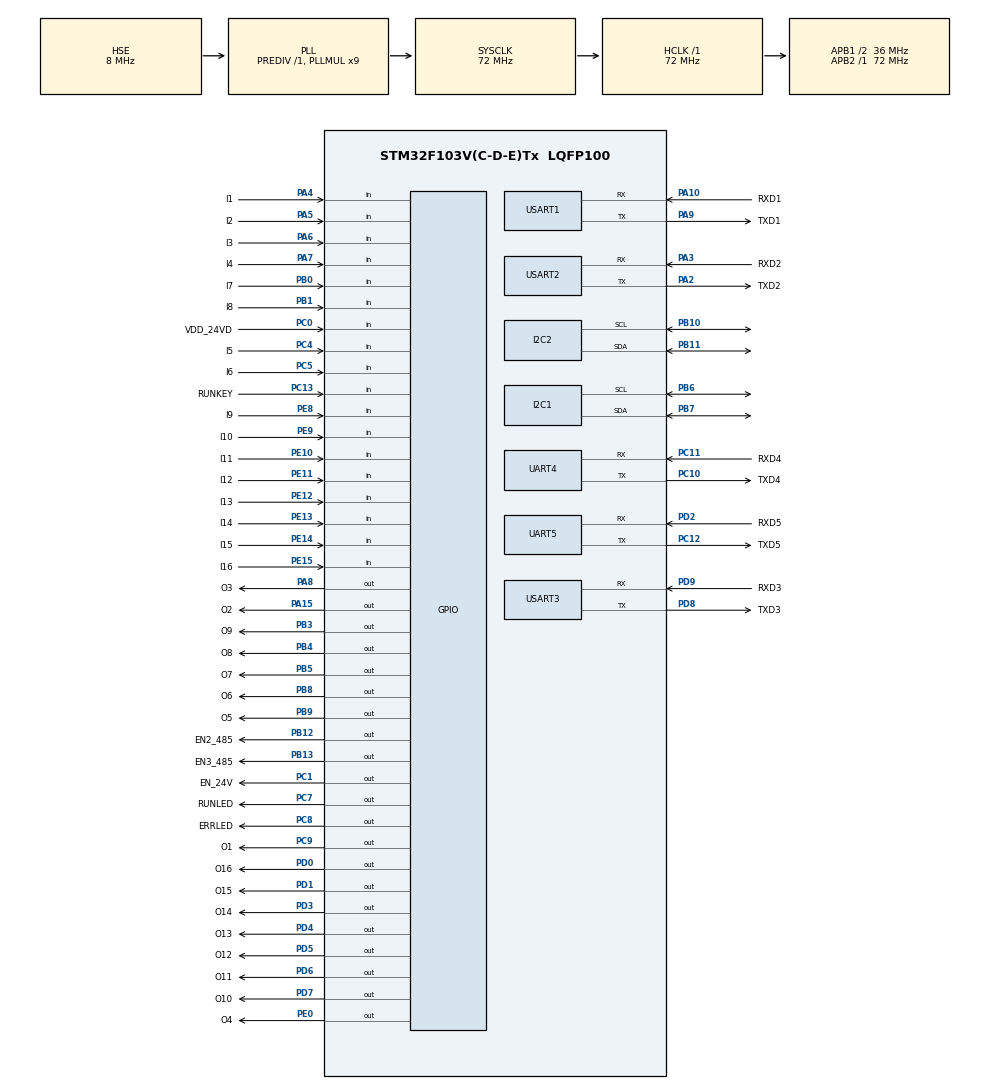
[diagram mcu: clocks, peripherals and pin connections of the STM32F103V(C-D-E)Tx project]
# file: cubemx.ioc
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Mcu.Family=STM32F1
Mcu.Name=STM32F103V(C-D-E)Tx
Mcu.Package=LQFP100
NVIC.PriorityGroup=NVIC_PRIORITYGROUP_4
NVIC.TIM1_UP_IRQn=true\:0\:0\:false\:false\:true\:true\:true\:true
NVIC.TIM2_IRQn=true\:0\:0\:false\:false\:true\:true\:true\:true
NVIC.TIM3_IRQn=true\:0\:0\:false\:false\:true\:true\:true\:true
NVIC.TIM4_IRQn=true\:0\:0\:false\:false\:true\:true\:true\:true
NVIC.TIM5_IRQn=true\:0\:0\:false\:false\:true\:true\:true\:true
NVIC.TIM6_IRQn=true\:0\:0\:false\:false\:true\:true\:true\:true
NVIC.TIM7_IRQn=true\:0\:0\:false\:false\:true\:true\:true\:true
NVIC.TIM8_UP_IRQn=true\:0\:0\:false\:false\:true\:true\:true\:true
NVIC.USART1_IRQn=true\:0\:0\:false\:false\:true\:true\:true\:true
OSC_IN.Mode=HSE-External-Oscillator
OSC_IN.Signal=RCC_OSC_IN
OSC_OUT.Mode=HSE-External-Oscillator
OSC_OUT.Signal=RCC_OSC_OUT
PA10.GPIO_Label=RXD1
PA10.Mode=Asynchronous
PA10.Signal=USART1_RX
PA13.Mode=Serial_Wire
PA13.Signal=SYS_JTMS-SWDIO
PA14.Mode=Serial_Wire
PA14.Signal=SYS_JTCK-SWCLK
PA15.GPIO_Label=O2
PA15.PinState=GPIO_PIN_RESET
PA15.Signal=GPIO_Output
PA2.GPIO_Label=TXD2
PA2.Mode=Asynchronous
PA2.Signal=USART2_TX
PA3.GPIO_Label=RXD2
PA3.Mode=Asynchronous
PA3.Signal=USART2_RX
PA4.GPIO_Label=I1
PA4.GPIO_Mode=GPIO_MODE_INPUT
PA4.GPIO_PuPd=GPIO_PULLUP
PA4.Signal=GPIO_Input
PA5.GPIO_Label=I2
PA5.GPIO_Mode=GPIO_MODE_INPUT
PA5.GPIO_PuPd=GPIO_PULLUP
PA5.Signal=GPIO_Input
PA6.GPIO_Label=I3
PA6.GPIO_Mode=GPIO_MODE_INPUT
PA6.GPIO_PuPd=GPIO_PULLUP
PA6.Signal=GPIO_Input
PA7.GPIO_Label=I4
PA7.GPIO_Mode=GPIO_MODE_INPUT
PA7.GPIO_PuPd=GPIO_PULLUP
PA7.Signal=GPIO_Input
PA8.GPIO_Label=O3
PA8.PinState=GPIO_PIN_RESET
PA8.Signal=GPIO_Output
PA9.GPIO_Label=TXD1
PA9.Mode=Asynchronous
PA9.Signal=USART1_TX
PB0.GPIO_Label=I7
PB0.GPIO_Mode=GPIO_MODE_INPUT
PB0.GPIO_PuPd=GPIO_PULLUP
PB0.Signal=GPIO_Input
PB1.GPIO_Label=I8
PB1.GPIO_Mode=GPIO_MODE_INPUT
PB1.GPIO_PuPd=GPIO_PULLUP
PB1.Signal=GPIO_Input
PB10.GPIO_Pu=GPIO_PULLUP
PB10.Mode=I2C
PB10.Signal=I2C2_SCL
PB11.GPIO_Pu=GPIO_PULLUP
PB11.Mode=I2C
PB11.Signal=I2C2_SDA
PB12.GPIO_Label=EN2_485
PB12.GPIO_Speed=GPIO_SPEED_FREQ_LOW
PB12.PinState=GPIO_PIN_SET
PB12.Signal=GPIO_Output
PB13.GPIO_Label=EN3_485
PB13.GPIO_Speed=GPIO_SPEED_FREQ_LOW
PB13.PinState=GPIO_PIN_SET
PB13.Signal=GPIO_Output
PB3.GPIO_Label=O9
PB3.GPIO_ModeDefaultOutputPP=GPIO_MODE_OUTPUT_PP
PB3.GPIO_PuPd=GPIO_NOPULL
PB3.GPIO_Speed=GPIO_SPEED_FREQ_LOW
PB3.PinState=GPIO_PIN_SET
PB3.Signal=GPIO_Output
PB4.GPIO_Label=O8
PB4.GPIO_ModeDefaultOutputPP=GPIO_MODE_OUTPUT_PP
PB4.GPIO_PuPd=GPIO_NOPULL
PB4.GPIO_Speed=GPIO_SPEED_FREQ_LOW
PB4.PinState=GPIO_PIN_SET
PB4.Signal=GPIO_Output
PB5.GPIO_Label=O7
PB5.GPIO_ModeDefaultOutputPP=GPIO_MODE_OUTPUT_PP
PB5.GPIO_PuPd=GPIO_NOPULL
PB5.GPIO_Speed=GPIO_SPEED_FREQ_LOW
PB5.PinState=GPIO_PIN_SET
PB5.Signal=GPIO_Output
PB6.GPIO_Pu=GPIO_PULLUP
PB6.Mode=I2C
PB6.Signal=I2C1_SCL
PB7.GPIO_Pu=GPIO_PULLUP
PB7.Mode=I2C
PB7.Signal=I2C1_SDA
PB8.GPIO_Label=O6
PB8.GPIO_ModeDefaultOutputPP=GPIO_MODE_OUTPUT_PP
PB8.GPIO_PuPd=GPIO_NOPULL
PB8.GPIO_Speed=GPIO_SPEED_FREQ_LOW
PB8.PinState=GPIO_PIN_SET
PB8.Signal=GPIO_Output
PB9.GPIO_Label=O5
PB9.GPIO_ModeDefaultOutputPP=GPIO_MODE_OUTPUT_PP
PB9.GPIO_PuPd=GPIO_NOPULL
PB9.GPIO_Speed=GPIO_SPEED_FREQ_LOW
PB9.PinState=GPIO_PIN_SET
PB9.Signal=GPIO_Output
PC0.GPIO_Label=VDD_24VD
PC0.Signal=GPIO_Input
PC1.GPIO_Label=EN_24V
PC1.GPIO_Speed=GPIO_SPEED_FREQ_LOW
PC1.Signal=GPIO_Output
PC10.GPIO_Label=TXD4
PC10.Mode=Asynchronous
PC10.Signal=UART4_TX
PC11.GPIO_Label=RXD4
PC11.Mode=Asynchronous
PC11.Signal=UART4_RX
PC12.GPIO_Label=TXD5
PC12.Mode=Asynchronous
PC12.Signal=UART5_TX
PC13-TAMPER-RTC.GPIO_Label=RUNKEY
PC13-TAMPER-RTC.Signal=GPIO_Input
PC14-OSC32_IN.Mode=LSE-External-Oscillator
PC14-OSC32_IN.Signal=RCC_OSC32_IN
PC15-OSC32_OUT.Mode=LSE-External-Oscillator
PC15-OSC32_OUT.Signal=RCC_OSC32_OUT
PC4.GPIO_Label=I5
PC4.GPIO_Mode=GPIO_MODE_INPUT
PC4.GPIO_PuPd=GPIO_PULLUP
PC4.Signal=GPIO_Input
PC5.GPIO_Label=I6
PC5.GPIO_Mode=GPIO_MODE_INPUT
PC5.GPIO_PuPd=GPIO_PULLUP
PC5.Signal=GPIO_Input
PC7.GPIO_Label=RUNLED
PC7.GPIO_ModeDefaultOutputPP=GPIO_MODE_OUTPUT_PP
PC7.GPIO_PuPd=GPIO_NOPULL
PC7.GPIO_Speed=GPIO_SPEED_FREQ_LOW
PC7.PinState=GPIO_PIN_SET
PC7.Signal=GPIO_Output
PC8.GPIO_Label=ERRLED
PC8.GPIO_ModeDefaultOutputPP=GPIO_MODE_OUTPUT_PP
PC8.GPIO_PuPd=GPIO_NOPULL
PC8.GPIO_Speed=GPIO_SPEED_FREQ_LOW
PC8.PinState=GPIO_PIN_SET
PC8.Signal=GPIO_Output
PC9.GPIO_Label=O1
PC9.PinState=GPIO_PIN_RESET
PC9.Signal=GPIO_Output
PD0.GPIO_Label=O16
PD0.GPIO_ModeDefaultOutputPP=GPIO_MODE_OUTPUT_PP
PD0.GPIO_PuPd=GPIO_NOPULL
PD0.GPIO_Speed=GPIO_SPEED_FREQ_LOW
PD0.PinState=GPIO_PIN_SET
PD0.Signal=GPIO_Output
PD1.GPIO_Label=O15
PD1.GPIO_ModeDefaultOutputPP=GPIO_MODE_OUTPUT_PP
PD1.GPIO_PuPd=GPIO_NOPULL
PD1.GPIO_Speed=GPIO_SPEED_FREQ_LOW
PD1.PinState=GPIO_PIN_SET
PD1.Signal=GPIO_Output
PD2.GPIO_Label=RXD5
PD2.Mode=Asynchronous
PD2.Signal=UART5_RX
PD3.GPIO_Label=O14
PD3.GPIO_ModeDefaultOutputPP=GPIO_MODE_OUTPUT_PP
PD3.GPIO_PuPd=GPIO_NOPULL
PD3.GPIO_Speed=GPIO_SPEED_FREQ_LOW
PD3.PinState=GPIO_PIN_SET
PD3.Signal=GPIO_Output
PD4.GPIO_Label=O13
PD4.GPIO_ModeDefaultOutputPP=GPIO_MODE_OUTPUT_PP
PD4.GPIO_PuPd=GPIO_NOPULL
PD4.GPIO_Speed=GPIO_SPEED_FREQ_LOW
PD4.PinState=GPIO_PIN_SET
PD4.Signal=GPIO_Output
PD5.GPIO_Label=O12
PD5.GPIO_ModeDefaultOutputPP=GPIO_MODE_OUTPUT_PP
PD5.GPIO_PuPd=GPIO_NOPULL
PD5.GPIO_Speed=GPIO_SPEED_FREQ_LOW
PD5.PinState=GPIO_PIN_SET
PD5.Signal=GPIO_Output
PD6.GPIO_Label=O11
PD6.GPIO_ModeDefaultOutputPP=GPIO_MODE_OUTPUT_PP
PD6.GPIO_PuPd=GPIO_NOPULL
PD6.GPIO_Speed=GPIO_SPEED_FREQ_LOW
PD6.PinState=GPIO_PIN_SET
PD6.Signal=GPIO_Output
PD7.GPIO_Label=O10
PD7.GPIO_ModeDefaultOutputPP=GPIO_MODE_OUTPUT_PP
PD7.GPIO_PuPd=GPIO_NOPULL
PD7.GPIO_Speed=GPIO_SPEED_FREQ_LOW
PD7.PinState=GPIO_PIN_SET
PD7.Signal=GPIO_Output
PD8.GPIO_Label=TXD3
PD8.Mode=Asynchronous
PD8.Signal=USART3_TX
PD9.GPIO_Label=RXD3
PD9.Mode=Asynchronous
PD9.Signal=USART3_RX
PE0.GPIO_Label=O4
PE0.GPIO_ModeDefaultOutputPP=GPIO_MODE_OUTPUT_PP
PE0.GPIO_PuPd=GPIO_NOPULL
PE0.GPIO_Speed=GPIO_SPEED_FREQ_LOW
PE0.PinState=GPIO_PIN_SET
PE0.Signal=GPIO_Output
PE10.GPIO_Label=I11
PE10.GPIO_Mode=GPIO_MODE_INPUT
PE10.GPIO_PuPd=GPIO_PULLUP
PE10.Signal=GPIO_Input
PE11.GPIO_Label=I12
PE11.GPIO_Mode=GPIO_MODE_INPUT
PE11.GPIO_PuPd=GPIO_PULLUP
PE11.Signal=GPIO_Input
PE12.GPIO_Label=I13
PE12.GPIO_Mode=GPIO_MODE_INPUT
PE12.GPIO_PuPd=GPIO_PULLUP
PE12.Signal=GPIO_Input
PE13.GPIO_Label=I14
PE13.GPIO_Mode=GPIO_MODE_INPUT
PE13.GPIO_PuPd=GPIO_PULLUP
PE13.Signal=GPIO_Input
PE14.GPIO_Label=I15
PE14.GPIO_Mode=GPIO_MODE_INPUT
PE14.GPIO_PuPd=GPIO_PULLUP
PE14.Signal=GPIO_Input
PE15.GPIO_Label=I16
PE15.GPIO_Mode=GPIO_MODE_INPUT
PE15.GPIO_PuPd=GPIO_PULLUP
PE15.Signal=GPIO_Input
PE8.GPIO_Label=I9
PE8.GPIO_Mode=GPIO_MODE_INPUT
PE8.GPIO_PuPd=GPIO_PULLUP
PE8.Signal=GPIO_Input
PE9.GPIO_Label=I10
PE9.GPIO_Mode=GPIO_MODE_INPUT
PE9.GPIO_PuPd=GPIO_PULLUP
PE9.Signal=GPIO_Input
ProjectManager.HeapSize=0x200
ProjectManager.StackSize=0x400
ProjectManager.TargetToolchain=MDK-ARM V5
RCC.AHBFreq_Value=72000000
RCC.APB1CLKDivider=RCC_HCLK_DIV2
RCC.APB1Freq_Value=36000000
RCC.APB1TimFreq_Value=72000000
RCC.APB2Freq_Value=72000000
RCC.APB2TimFreq_Value=72000000
RCC.HCLKFreq_Value=72000000
RCC.PLLMUL=RCC_PLL_MUL9
RCC.PLLSourceVirtual=RCC_PLLSOURCE_HSE
RCC.SYSCLKFreq_VALUE=72000000
RCC.SYSCLKSource=RCC_SYSCLKSOURCE_PLLCLK
RCC.USBFreq_Value=72000000
TIM1.AutoReloadPreload=TIM_AUTORELOAD_PRELOAD_ENABLE
TIM1.Period=5000-1
TIM1.Prescaler=7200-1
TIM2.AutoReloadPreload=TIM_AUTORELOAD_PRELOAD_ENABLE
TIM2.Period=5000-1
TIM2.Prescaler=7200-1
TIM3.AutoReloadPreload=TIM_AUTORELOAD_PRELOAD_ENABLE
TIM3.Period=5000-1
TIM3.Prescaler=7200-1
TIM4.AutoReloadPreload=TIM_AUTORELOAD_PRELOAD_ENABLE
TIM4.Period=5000-1
TIM4.Prescaler=7200-1
TIM5.AutoReloadPreload=TIM_AUTORELOAD_PRELOAD_ENABLE
TIM5.Period=5000-1
TIM5.Prescaler=7200-1
TIM6.AutoReloadPreload=TIM_AUTORELOAD_PRELOAD_ENABLE
TIM6.Period=5000-1
TIM6.Prescaler=7200-1
TIM7.AutoReloadPreload=TIM_AUTORELOAD_PRELOAD_ENABLE
TIM7.Period=5000-1
TIM7.Prescaler=7200-1
TIM8.AutoReloadPreload=TIM_AUTORELOAD_PRELOAD_ENABLE
TIM8.Period=5000-1
TIM8.Prescaler=7200-1
UART4.VirtualMode=Asynchronous
UART5.VirtualMode=Asynchronous
USART1.VirtualMode=VM_ASYNC
USART2.VirtualMode=VM_ASYNC
USART3.VirtualMode=VM_ASYNC
VP_TIM1_VS_ClockSourceINT.Mode=Internal
VP_TIM2_VS_ClockSourceINT.Mode=Internal
VP_TIM3_VS_ClockSourceINT.Mode=Internal
VP_TIM4_VS_ClockSourceINT.Mode=Internal
VP_TIM5_VS_ClockSourceINT.Mode=Internal
VP_TIM6_VS_ClockSourceINT.Mode=Enable_Timer
VP_TIM7_VS_ClockSourceINT.Mode=Enable_Timer
VP_TIM8_VS_ClockSourceINT.Mode=Internal
board=custom

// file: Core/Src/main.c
/* USER CODE BEGIN Header */
/**
  ******************************************************************************
  * @file           : main.c
  * @brief          : Main program body
  ******************************************************************************
  * @attention
  *
  * <h2><center>&copy; Copyright (c) 2022 STMicroelectronics.
  * All rights reserved.</center></h2>
  *
  * This software component is licensed by ST under BSD 3-Clause license,
  * the "License"; You may not use this file except in compliance with the
  * License. You may obtain a copy of the License at:
  *                        opensource.org/licenses/BSD-3-Clause
  *
  ******************************************************************************
  */
/* USER CODE END Header */
#include "main.h"

/* USER CODE BEGIN Includes */
#include "bsp.h"
/* USER CODE END Includes */

I2C_HandleTypeDef hi2c1;
I2C_HandleTypeDef hi2c2;

TIM_HandleTypeDef htim1;
TIM_HandleTypeDef htim2;
TIM_HandleTypeDef htim3;
TIM_HandleTypeDef htim4;
TIM_HandleTypeDef htim5;
TIM_HandleTypeDef htim6;
TIM_HandleTypeDef htim7;
TIM_HandleTypeDef htim8;

UART_HandleTypeDef huart4;
UART_HandleTypeDef huart5;
UART_HandleTypeDef huart1;
UART_HandleTypeDef huart2;
UART_HandleTypeDef huart3;

void SystemClock_Config(void);
static void MX_GPIO_Init(void);
static void MX_I2C1_Init(void);
static void MX_I2C2_Init(void);
static void MX_UART4_Init(void);
static void MX_UART5_Init(void);
static void MX_USART1_UART_Init(void);
static void MX_USART2_UART_Init(void);
static void MX_USART3_UART_Init(void);
static void MX_TIM1_Init(void);
static void MX_TIM2_Init(void);
static void MX_TIM3_Init(void);
static void MX_TIM5_Init(void);
static void MX_TIM4_Init(void);
static void MX_TIM6_Init(void);
static void MX_TIM7_Init(void);
static void MX_TIM8_Init(void);

/* USER CODE BEGIN 0 */

uint8_t tx_buff[]={0,1,2,3,4,5,6,7,8,9};
uint8_t rx_buff[10];

/* USER CODE END 0 */

int main(void)
{

  /* MCU Configuration--------------------------------------------------------*/

  /* Reset of all peripherals, Initializes the Flash interface and the Systick. */
  HAL_Init();

  /* Configure the system clock */
  SystemClock_Config();

  /* Initialize all configured peripherals */
  MX_GPIO_Init();
  MX_I2C1_Init();
  MX_I2C2_Init();
  MX_UART4_Init();
  MX_UART5_Init();
  MX_USART1_UART_Init();
  MX_USART2_UART_Init();
  MX_USART3_UART_Init();
  MX_TIM1_Init();
  MX_TIM2_Init();
  MX_TIM3_Init();
  MX_TIM5_Init();
  MX_TIM4_Init();
  MX_TIM6_Init();
  MX_TIM7_Init();
  MX_TIM8_Init();
  /* USER CODE BEGIN 2 */

    wait_ready();	//	用户初始化程序

  /* USER CODE END 2 */

  /* Infinite loop */
    while (1)
    {

    /* USER CODE BEGIN 3 */

        work_flow();						//执行用户的loop程序
//		HAL_GPIO_TogglePin(ERRLED_GPIO_Port,ERRLED_Pin);
//				HAL_GPIO_TogglePin(M_O15_GPIO_Port,M_O15_Pin);
//		HAL_Delay(500);
    }
  /* USER CODE END 3 */
}

void SystemClock_Config(void)
{
  RCC_OscInitTypeDef RCC_OscInitStruct = {0};
  RCC_ClkInitTypeDef RCC_ClkInitStruct = {0};

  /** Initializes the RCC Oscillators according to the specified parameters
  * in the RCC_OscInitTypeDef structure.
  */
  RCC_OscInitStruct.OscillatorType = RCC_OSCILLATORTYPE_HSE;
  RCC_OscInitStruct.HSEState = RCC_HSE_ON;
  RCC_OscInitStruct.HSEPredivValue = RCC_HSE_PREDIV_DIV1;
  RCC_OscInitStruct.HSIState = RCC_HSI_ON;
  RCC_OscInitStruct.PLL.PLLState = RCC_PLL_ON;
  RCC_OscInitStruct.PLL.PLLSource = RCC_PLLSOURCE_HSE;
  RCC_OscInitStruct.PLL.PLLMUL = RCC_PLL_MUL9;
  if (HAL_RCC_OscConfig(&RCC_OscInitStruct) != HAL_OK)
  {
    Error_Handler();
  }

  /** Initializes the CPU, AHB and APB buses clocks
  */
  RCC_ClkInitStruct.ClockType = RCC_CLOCKTYPE_HCLK|RCC_CLOCKTYPE_SYSCLK
                              |RCC_CLOCKTYPE_PCLK1|RCC_CLOCKTYPE_PCLK2;
  RCC_ClkInitStruct.SYSCLKSource = RCC_SYSCLKSOURCE_PLLCLK;
  RCC_ClkInitStruct.AHBCLKDivider = RCC_SYSCLK_DIV1;
  RCC_ClkInitStruct.APB1CLKDivider = RCC_HCLK_DIV2;
  RCC_ClkInitStruct.APB2CLKDivider = RCC_HCLK_DIV1;

  if (HAL_RCC_ClockConfig(&RCC_ClkInitStruct, FLASH_LATENCY_2) != HAL_OK)
  {
    Error_Handler();
  }
}

static void MX_I2C1_Init(void)
{

  hi2c1.Instance = I2C1;
  hi2c1.Init.ClockSpeed = 100000;
  hi2c1.Init.DutyCycle = I2C_DUTYCYCLE_2;
  hi2c1.Init.OwnAddress1 = 0;
  hi2c1.Init.AddressingMode = I2C_ADDRESSINGMODE_7BIT;
  hi2c1.Init.DualAddressMode = I2C_DUALADDRESS_DISABLE;
  hi2c1.Init.OwnAddress2 = 0;
  hi2c1.Init.GeneralCallMode = I2C_GENERALCALL_DISABLE;
  hi2c1.Init.NoStretchMode = I2C_NOSTRETCH_DISABLE;
  if (HAL_I2C_Init(&hi2c1) != HAL_OK)
  {
    Error_Handler();
  }

}

static void MX_I2C2_Init(void)
{

  hi2c2.Instance = I2C2;
  hi2c2.Init.ClockSpeed = 100000;
  hi2c2.Init.DutyCycle = I2C_DUTYCYCLE_2;
  hi2c2.Init.OwnAddress1 = 0;
  hi2c2.Init.AddressingMode = I2C_ADDRESSINGMODE_7BIT;
  hi2c2.Init.DualAddressMode = I2C_DUALADDRESS_DISABLE;
  hi2c2.Init.OwnAddress2 = 0;
  hi2c2.Init.GeneralCallMode = I2C_GENERALCALL_DISABLE;
  hi2c2.Init.NoStretchMode = I2C_NOSTRETCH_DISABLE;
  if (HAL_I2C_Init(&hi2c2) != HAL_OK)
  {
    Error_Handler();
  }

}

static void MX_TIM1_Init(void)
{

  TIM_ClockConfigTypeDef sClockSourceConfig = {0};
  TIM_MasterConfigTypeDef sMasterConfig = {0};

  htim1.Instance = TIM1;
  htim1.Init.Prescaler = 7200-1;
  htim1.Init.CounterMode = TIM_COUNTERMODE_UP;
  htim1.Init.Period = 5000-1;
  htim1.Init.ClockDivision = TIM_CLOCKDIVISION_DIV1;
  htim1.Init.RepetitionCounter = 0;
  htim1.Init.AutoReloadPreload = TIM_AUTORELOAD_PRELOAD_ENABLE;
  if (HAL_TIM_Base_Init(&htim1) != HAL_OK)
  {
    Error_Handler();
  }
  sClockSourceConfig.ClockSource = TIM_CLOCKSOURCE_INTERNAL;
  if (HAL_TIM_ConfigClockSource(&htim1, &sClockSourceConfig) != HAL_OK)
  {
    Error_Handler();
  }
  sMasterConfig.MasterOutputTrigger = TIM_TRGO_RESET;
  sMasterConfig.MasterSlaveMode = TIM_MASTERSLAVEMODE_DISABLE;
  if (HAL_TIMEx_MasterConfigSynchronization(&htim1, &sMasterConfig) != HAL_OK)
  {
    Error_Handler();
  }

}

static void MX_TIM2_Init(void)
{

  TIM_ClockConfigTypeDef sClockSourceConfig = {0};
  TIM_MasterConfigTypeDef sMasterConfig = {0};

  htim2.Instance = TIM2;
  htim2.Init.Prescaler = 7200-1;
  htim2.Init.CounterMode = TIM_COUNTERMODE_UP;
  htim2.Init.Period = 5000-1;
  htim2.Init.ClockDivision = TIM_CLOCKDIVISION_DIV1;
  htim2.Init.AutoReloadPreload = TIM_AUTORELOAD_PRELOAD_ENABLE;
  if (HAL_TIM_Base_Init(&htim2) != HAL_OK)
  {
    Error_Handler();
  }
  sClockSourceConfig.ClockSource = TIM_CLOCKSOURCE_INTERNAL;
  if (HAL_TIM_ConfigClockSource(&htim2, &sClockSourceConfig) != HAL_OK)
  {
    Error_Handler();
  }
  sMasterConfig.MasterOutputTrigger = TIM_TRGO_RESET;
  sMasterConfig.MasterSlaveMode = TIM_MASTERSLAVEMODE_DISABLE;
  if (HAL_TIMEx_MasterConfigSynchronization(&htim2, &sMasterConfig) != HAL_OK)
  {
    Error_Handler();
  }

}

static void MX_TIM3_Init(void)
{

  TIM_ClockConfigTypeDef sClockSourceConfig = {0};
  TIM_MasterConfigTypeDef sMasterConfig = {0};

  htim3.Instance = TIM3;
  htim3.Init.Prescaler = 7200-1;
  htim3.Init.CounterMode = TIM_COUNTERMODE_UP;
  htim3.Init.Period = 5000-1;
  htim3.Init.ClockDivision = TIM_CLOCKDIVISION_DIV1;
  htim3.Init.AutoReloadPreload = TIM_AUTORELOAD_PRELOAD_ENABLE;
  if (HAL_TIM_Base_Init(&htim3) != HAL_OK)
  {
    Error_Handler();
  }
  sClockSourceConfig.ClockSource = TIM_CLOCKSOURCE_INTERNAL;
  if (HAL_TIM_ConfigClockSource(&htim3, &sClockSourceConfig) != HAL_OK)
  {
    Error_Handler();
  }
  sMasterConfig.MasterOutputTrigger = TIM_TRGO_RESET;
  sMasterConfig.MasterSlaveMode = TIM_MASTERSLAVEMODE_DISABLE;
  if (HAL_TIMEx_MasterConfigSynchronization(&htim3, &sMasterConfig) != HAL_OK)
  {
    Error_Handler();
  }

}

static void MX_TIM4_Init(void)
{

  TIM_ClockConfigTypeDef sClockSourceConfig = {0};
  TIM_MasterConfigTypeDef sMasterConfig = {0};

  htim4.Instance = TIM4;
  htim4.Init.Prescaler = 7200-1;
  htim4.Init.CounterMode = TIM_COUNTERMODE_UP;
  htim4.Init.Period = 5000-1;
  htim4.Init.ClockDivision = TIM_CLOCKDIVISION_DIV1;
  htim4.Init.AutoReloadPreload = TIM_AUTORELOAD_PRELOAD_ENABLE;
  if (HAL_TIM_Base_Init(&htim4) != HAL_OK)
  {
    Error_Handler();
  }
  sClockSourceConfig.ClockSource = TIM_CLOCKSOURCE_INTERNAL;
  if (HAL_TIM_ConfigClockSource(&htim4, &sClockSourceConfig) != HAL_OK)
  {
    Error_Handler();
  }
  sMasterConfig.MasterOutputTrigger = TIM_TRGO_RESET;
  sMasterConfig.MasterSlaveMode = TIM_MASTERSLAVEMODE_DISABLE;
  if (HAL_TIMEx_MasterConfigSynchronization(&htim4, &sMasterConfig) != HAL_OK)
  {
    Error_Handler();
  }

}

static void MX_TIM5_Init(void)
{

  TIM_ClockConfigTypeDef sClockSourceConfig = {0};
  TIM_MasterConfigTypeDef sMasterConfig = {0};

  htim5.Instance = TIM5;
  htim5.Init.Prescaler = 7200-1;
  htim5.Init.CounterMode = TIM_COUNTERMODE_UP;
  htim5.Init.Period = 5000-1;
  htim5.Init.ClockDivision = TIM_CLOCKDIVISION_DIV1;
  htim5.Init.AutoReloadPreload = TIM_AUTORELOAD_PRELOAD_ENABLE;
  if (HAL_TIM_Base_Init(&htim5) != HAL_OK)
  {
    Error_Handler();
  }
  sClockSourceConfig.ClockSource = TIM_CLOCKSOURCE_INTERNAL;
  if (HAL_TIM_ConfigClockSource(&htim5, &sClockSourceConfig) != HAL_OK)
  {
    Error_Handler();
  }
  sMasterConfig.MasterOutputTrigger = TIM_TRGO_RESET;
  sMasterConfig.MasterSlaveMode = TIM_MASTERSLAVEMODE_DISABLE;
  if (HAL_TIMEx_MasterConfigSynchronization(&htim5, &sMasterConfig) != HAL_OK)
  {
    Error_Handler();
  }

}

static void MX_TIM6_Init(void)
{

  TIM_MasterConfigTypeDef sMasterConfig = {0};

  htim6.Instance = TIM6;
  htim6.Init.Prescaler = 7200-1;
  htim6.Init.CounterMode = TIM_COUNTERMODE_UP;
  htim6.Init.Period = 5000-1;
  htim6.Init.AutoReloadPreload = TIM_AUTORELOAD_PRELOAD_ENABLE;
  if (HAL_TIM_Base_Init(&htim6) != HAL_OK)
  {
    Error_Handler();
  }
  sMasterConfig.MasterOutputTrigger = TIM_TRGO_RESET;
  sMasterConfig.MasterSlaveMode = TIM_MASTERSLAVEMODE_DISABLE;
  if (HAL_TIMEx_MasterConfigSynchronization(&htim6, &sMasterConfig) != HAL_OK)
  {
    Error_Handler();
  }

}

static void MX_TIM7_Init(void)
{

  TIM_MasterConfigTypeDef sMasterConfig = {0};

  htim7.Instance = TIM7;
  htim7.Init.Prescaler = 7200-1;
  htim7.Init.CounterMode = TIM_COUNTERMODE_UP;
  htim7.Init.Period = 5000-1;
  htim7.Init.AutoReloadPreload = TIM_AUTORELOAD_PRELOAD_ENABLE;
  if (HAL_TIM_Base_Init(&htim7) != HAL_OK)
  {
    Error_Handler();
  }
  sMasterConfig.MasterOutputTrigger = TIM_TRGO_RESET;
  sMasterConfig.MasterSlaveMode = TIM_MASTERSLAVEMODE_DISABLE;
  if (HAL_TIMEx_MasterConfigSynchronization(&htim7, &sMasterConfig) != HAL_OK)
  {
    Error_Handler();
  }

}

static void MX_TIM8_Init(void)
{

  TIM_ClockConfigTypeDef sClockSourceConfig = {0};
  TIM_MasterConfigTypeDef sMasterConfig = {0};

  htim8.Instance = TIM8;
  htim8.Init.Prescaler = 7200-1;
  htim8.Init.CounterMode = TIM_COUNTERMODE_UP;
  htim8.Init.Period = 5000-1;
  htim8.Init.ClockDivision = TIM_CLOCKDIVISION_DIV1;
  htim8.Init.RepetitionCounter = 0;
  htim8.Init.AutoReloadPreload = TIM_AUTORELOAD_PRELOAD_ENABLE;
  if (HAL_TIM_Base_Init(&htim8) != HAL_OK)
  {
    Error_Handler();
  }
  sClockSourceConfig.ClockSource = TIM_CLOCKSOURCE_INTERNAL;
  if (HAL_TIM_ConfigClockSource(&htim8, &sClockSourceConfig) != HAL_OK)
  {
    Error_Handler();
  }
  sMasterConfig.MasterOutputTrigger = TIM_TRGO_RESET;
  sMasterConfig.MasterSlaveMode = TIM_MASTERSLAVEMODE_DISABLE;
  if (HAL_TIMEx_MasterConfigSynchronization(&htim8, &sMasterConfig) != HAL_OK)
  {
    Error_Handler();
  }

}

static void MX_UART4_Init(void)
{

  huart4.Instance = UART4;
  huart4.Init.BaudRate = 115200;
  huart4.Init.WordLength = UART_WORDLENGTH_8B;
  huart4.Init.StopBits = UART_STOPBITS_1;
  huart4.Init.Parity = UART_PARITY_NONE;
  huart4.Init.Mode = UART_MODE_TX_RX;
  huart4.Init.HwFlowCtl = UART_HWCONTROL_NONE;
  huart4.Init.OverSampling = UART_OVERSAMPLING_16;
  if (HAL_UART_Init(&huart4) != HAL_OK)
  {
    Error_Handler();
  }

}

static void MX_UART5_Init(void)
{

  huart5.Instance = UART5;
  huart5.Init.BaudRate = 115200;
  huart5.Init.WordLength = UART_WORDLENGTH_8B;
  huart5.Init.StopBits = UART_STOPBITS_1;
  huart5.Init.Parity = UART_PARITY_NONE;
  huart5.Init.Mode = UART_MODE_TX_RX;
  huart5.Init.HwFlowCtl = UART_HWCONTROL_NONE;
  huart5.Init.OverSampling = UART_OVERSAMPLING_16;
  if (HAL_UART_Init(&huart5) != HAL_OK)
  {
    Error_Handler();
  }

}

static void MX_USART1_UART_Init(void)
{

  huart1.Instance = USART1;
  huart1.Init.BaudRate = 115200;
  huart1.Init.WordLength = UART_WORDLENGTH_8B;
  huart1.Init.StopBits = UART_STOPBITS_1;
  huart1.Init.Parity = UART_PARITY_NONE;
  huart1.Init.Mode = UART_MODE_TX_RX;
  huart1.Init.HwFlowCtl = UART_HWCONTROL_NONE;
  huart1.Init.OverSampling = UART_OVERSAMPLING_16;
  if (HAL_UART_Init(&huart1) != HAL_OK)
  {
    Error_Handler();
  }

}

static void MX_USART2_UART_Init(void)
{

  huart2.Instance = USART2;
  huart2.Init.BaudRate = 115200;
  huart2.Init.WordLength = UART_WORDLENGTH_8B;
  huart2.Init.StopBits = UART_STOPBITS_1;
  huart2.Init.Parity = UART_PARITY_NONE;
  huart2.Init.Mode = UART_MODE_TX_RX;
  huart2.Init.HwFlowCtl = UART_HWCONTROL_NONE;
  huart2.Init.OverSampling = UART_OVERSAMPLING_16;
  if (HAL_UART_Init(&huart2) != HAL_OK)
  {
    Error_Handler();
  }

}

static void MX_USART3_UART_Init(void)
{

  huart3.Instance = USART3;
  huart3.Init.BaudRate = 115200;
  huart3.Init.WordLength = UART_WORDLENGTH_8B;
  huart3.Init.StopBits = UART_STOPBITS_1;
  huart3.Init.Parity = UART_PARITY_NONE;
  huart3.Init.Mode = UART_MODE_TX_RX;
  huart3.Init.HwFlowCtl = UART_HWCONTROL_NONE;
  huart3.Init.OverSampling = UART_OVERSAMPLING_16;
  if (HAL_UART_Init(&huart3) != HAL_OK)
  {
    Error_Handler();
  }

}

static void MX_GPIO_Init(void)
{
  GPIO_InitTypeDef GPIO_InitStruct = {0};

  /* GPIO Ports Clock Enable */
  __HAL_RCC_GPIOC_CLK_ENABLE();
  __HAL_RCC_GPIOA_CLK_ENABLE();
  __HAL_RCC_GPIOB_CLK_ENABLE();
  __HAL_RCC_GPIOE_CLK_ENABLE();
  __HAL_RCC_GPIOD_CLK_ENABLE();

  /*Configure GPIO pin Output Level */
  HAL_GPIO_WritePin(GPIOC, EN_24V_Pin|O1_Pin, GPIO_PIN_RESET);

  /*Configure GPIO pin Output Level */
  HAL_GPIO_WritePin(GPIOB, EN2_485_Pin|EN3_485_Pin|O9_Pin|O8_Pin
                          |O7_Pin|O6_Pin|O5_Pin, GPIO_PIN_SET);

  /*Configure GPIO pin Output Level */
  HAL_GPIO_WritePin(GPIOC, RUNLED_Pin|ERRLED_Pin, GPIO_PIN_SET);

  /*Configure GPIO pin Output Level */
  HAL_GPIO_WritePin(GPIOA, O3_Pin|O2_Pin, GPIO_PIN_RESET);

  /*Configure GPIO pin Output Level */
  HAL_GPIO_WritePin(GPIOD, O16_Pin|O15_Pin|O14_Pin|O13_Pin
                          |O12_Pin|O11_Pin|O10_Pin, GPIO_PIN_SET);

  /*Configure GPIO pin Output Level */
  HAL_GPIO_WritePin(O4_GPIO_Port, O4_Pin, GPIO_PIN_SET);

  /*Configure GPIO pins : RUNKEY_Pin VDD_24VD_Pin */
  GPIO_InitStruct.Pin = RUNKEY_Pin|VDD_24VD_Pin;
  GPIO_InitStruct.Mode = GPIO_MODE_INPUT;
  GPIO_InitStruct.Pull = GPIO_NOPULL;
  HAL_GPIO_Init(GPIOC, &GPIO_InitStruct);

  /*Configure GPIO pins : EN_24V_Pin RUNLED_Pin ERRLED_Pin O1_Pin */
  GPIO_InitStruct.Pin = EN_24V_Pin|RUNLED_Pin|ERRLED_Pin|O1_Pin;
  GPIO_InitStruct.Mode = GPIO_MODE_OUTPUT_PP;
  GPIO_InitStruct.Pull = GPIO_NOPULL;
  GPIO_InitStruct.Speed = GPIO_SPEED_FREQ_LOW;
  HAL_GPIO_Init(GPIOC, &GPIO_InitStruct);

  /*Configure GPIO pins : I1_Pin I2_Pin I3_Pin I4_Pin */
  GPIO_InitStruct.Pin = I1_Pin|I2_Pin|I3_Pin|I4_Pin;
  GPIO_InitStruct.Mode = GPIO_MODE_INPUT;
  GPIO_InitStruct.Pull = GPIO_PULLUP;
  HAL_GPIO_Init(GPIOA, &GPIO_InitStruct);

  /*Configure GPIO pins : I5_Pin I6_Pin */
  GPIO_InitStruct.Pin = I5_Pin|I6_Pin;
  GPIO_InitStruct.Mode = GPIO_MODE_INPUT;
  GPIO_InitStruct.Pull = GPIO_PULLUP;
  HAL_GPIO_Init(GPIOC, &GPIO_InitStruct);

  /*Configure GPIO pins : I7_Pin I8_Pin */
  GPIO_InitStruct.Pin = I7_Pin|I8_Pin;
  GPIO_InitStruct.Mode = GPIO_MODE_INPUT;
  GPIO_InitStruct.Pull = GPIO_PULLUP;
  HAL_GPIO_Init(GPIOB, &GPIO_InitStruct);

  /*Configure GPIO pins : I9_Pin I10_Pin I11_Pin I12_Pin
                           I13_Pin I14_Pin I15_Pin I16_Pin */
  GPIO_InitStruct.Pin = I9_Pin|I10_Pin|I11_Pin|I12_Pin
                          |I13_Pin|I14_Pin|I15_Pin|I16_Pin;
  GPIO_InitStruct.Mode = GPIO_MODE_INPUT;
  GPIO_InitStruct.Pull = GPIO_PULLUP;
  HAL_GPIO_Init(GPIOE, &GPIO_InitStruct);

  /*Configure GPIO pins : EN2_485_Pin EN3_485_Pin O9_Pin O8_Pin
                           O7_Pin O6_Pin O5_Pin */
  GPIO_InitStruct.Pin = EN2_485_Pin|EN3_485_Pin|O9_Pin|O8_Pin
                          |O7_Pin|O6_Pin|O5_Pin;
  GPIO_InitStruct.Mode = GPIO_MODE_OUTPUT_PP;
  GPIO_InitStruct.Pull = GPIO_NOPULL;
  GPIO_InitStruct.Speed = GPIO_SPEED_FREQ_LOW;
  HAL_GPIO_Init(GPIOB, &GPIO_InitStruct);

  /*Configure GPIO pins : O3_Pin O2_Pin */
  GPIO_InitStruct.Pin = O3_Pin|O2_Pin;
  GPIO_InitStruct.Mode = GPIO_MODE_OUTPUT_PP;
  GPIO_InitStruct.Pull = GPIO_NOPULL;
  GPIO_InitStruct.Speed = GPIO_SPEED_FREQ_LOW;
  HAL_GPIO_Init(GPIOA, &GPIO_InitStruct);

  /*Configure GPIO pins : O16_Pin O15_Pin O14_Pin O13_Pin
                           O12_Pin O11_Pin O10_Pin */
  GPIO_InitStruct.Pin = O16_Pin|O15_Pin|O14_Pin|O13_Pin
                          |O12_Pin|O11_Pin|O10_Pin;
  GPIO_InitStruct.Mode = GPIO_MODE_OUTPUT_PP;
  GPIO_InitStruct.Pull = GPIO_NOPULL;
  GPIO_InitStruct.Speed = GPIO_SPEED_FREQ_LOW;
  HAL_GPIO_Init(GPIOD, &GPIO_InitStruct);

  /*Configure GPIO pin : O4_Pin */
  GPIO_InitStruct.Pin = O4_Pin;
  GPIO_InitStruct.Mode = GPIO_MODE_OUTPUT_PP;
  GPIO_InitStruct.Pull = GPIO_NOPULL;
  GPIO_InitStruct.Speed = GPIO_SPEED_FREQ_LOW;
  HAL_GPIO_Init(O4_GPIO_Port, &GPIO_InitStruct);

}

void Error_Handler(void)
{
    __disable_irq();
    while (1)
    {
    }
}
